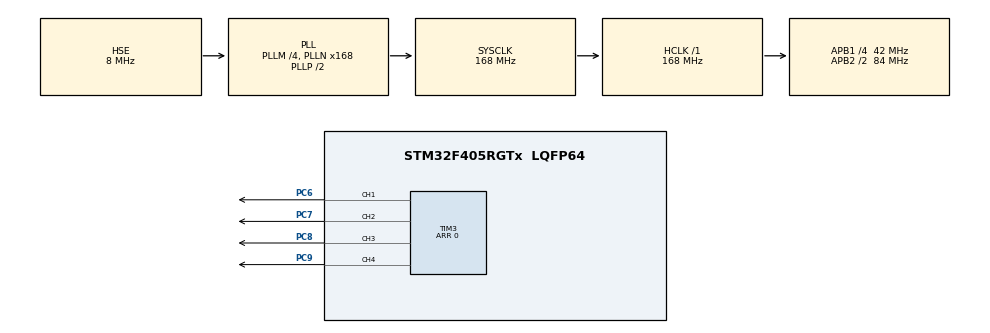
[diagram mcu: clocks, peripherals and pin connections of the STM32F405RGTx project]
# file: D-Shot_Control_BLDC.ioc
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Dma.Request0=TIM3_CH1/TRIG
Dma.Request1=TIM3_CH2
Dma.Request2=TIM3_CH3
Dma.Request3=TIM3_CH4/UP
Dma.TIM3_CH1/TRIG.0.Direction=DMA_MEMORY_TO_PERIPH
Dma.TIM3_CH1/TRIG.0.FIFOMode=DMA_FIFOMODE_ENABLE
Dma.TIM3_CH1/TRIG.0.FIFOThreshold=DMA_FIFO_THRESHOLD_1QUARTERFULL
Dma.TIM3_CH1/TRIG.0.Instance=DMA1_Stream4
Dma.TIM3_CH1/TRIG.0.MemBurst=DMA_MBURST_SINGLE
Dma.TIM3_CH1/TRIG.0.MemDataAlignment=DMA_MDATAALIGN_WORD
Dma.TIM3_CH1/TRIG.0.MemInc=DMA_MINC_ENABLE
Dma.TIM3_CH1/TRIG.0.Mode=DMA_NORMAL
Dma.TIM3_CH1/TRIG.0.PeriphBurst=DMA_PBURST_SINGLE
Dma.TIM3_CH1/TRIG.0.PeriphDataAlignment=DMA_PDATAALIGN_WORD
Dma.TIM3_CH1/TRIG.0.PeriphInc=DMA_PINC_DISABLE
Dma.TIM3_CH1/TRIG.0.Priority=DMA_PRIORITY_HIGH
Dma.TIM3_CH2.1.Direction=DMA_MEMORY_TO_PERIPH
Dma.TIM3_CH2.1.FIFOMode=DMA_FIFOMODE_ENABLE
Dma.TIM3_CH2.1.FIFOThreshold=DMA_FIFO_THRESHOLD_1QUARTERFULL
Dma.TIM3_CH2.1.Instance=DMA1_Stream5
Dma.TIM3_CH2.1.MemBurst=DMA_MBURST_SINGLE
Dma.TIM3_CH2.1.MemDataAlignment=DMA_MDATAALIGN_WORD
Dma.TIM3_CH2.1.MemInc=DMA_MINC_ENABLE
Dma.TIM3_CH2.1.Mode=DMA_NORMAL
Dma.TIM3_CH2.1.PeriphBurst=DMA_PBURST_SINGLE
Dma.TIM3_CH2.1.PeriphDataAlignment=DMA_PDATAALIGN_WORD
Dma.TIM3_CH2.1.PeriphInc=DMA_PINC_DISABLE
Dma.TIM3_CH2.1.Priority=DMA_PRIORITY_HIGH
Dma.TIM3_CH3.2.Direction=DMA_MEMORY_TO_PERIPH
Dma.TIM3_CH3.2.FIFOMode=DMA_FIFOMODE_ENABLE
Dma.TIM3_CH3.2.FIFOThreshold=DMA_FIFO_THRESHOLD_1QUARTERFULL
Dma.TIM3_CH3.2.Instance=DMA1_Stream7
Dma.TIM3_CH3.2.MemBurst=DMA_MBURST_SINGLE
Dma.TIM3_CH3.2.MemDataAlignment=DMA_MDATAALIGN_WORD
Dma.TIM3_CH3.2.MemInc=DMA_MINC_ENABLE
Dma.TIM3_CH3.2.Mode=DMA_NORMAL
Dma.TIM3_CH3.2.PeriphBurst=DMA_PBURST_SINGLE
Dma.TIM3_CH3.2.PeriphDataAlignment=DMA_PDATAALIGN_WORD
Dma.TIM3_CH3.2.PeriphInc=DMA_PINC_DISABLE
Dma.TIM3_CH3.2.Priority=DMA_PRIORITY_HIGH
Dma.TIM3_CH4/UP.3.Direction=DMA_MEMORY_TO_PERIPH
Dma.TIM3_CH4/UP.3.FIFOMode=DMA_FIFOMODE_ENABLE
Dma.TIM3_CH4/UP.3.FIFOThreshold=DMA_FIFO_THRESHOLD_1QUARTERFULL
Dma.TIM3_CH4/UP.3.Instance=DMA1_Stream2
Dma.TIM3_CH4/UP.3.MemBurst=DMA_MBURST_SINGLE
Dma.TIM3_CH4/UP.3.MemDataAlignment=DMA_MDATAALIGN_WORD
Dma.TIM3_CH4/UP.3.MemInc=DMA_MINC_ENABLE
Dma.TIM3_CH4/UP.3.Mode=DMA_NORMAL
Dma.TIM3_CH4/UP.3.PeriphBurst=DMA_PBURST_SINGLE
Dma.TIM3_CH4/UP.3.PeriphDataAlignment=DMA_PDATAALIGN_WORD
Dma.TIM3_CH4/UP.3.PeriphInc=DMA_PINC_DISABLE
Dma.TIM3_CH4/UP.3.Priority=DMA_PRIORITY_HIGH
Mcu.Family=STM32F4
Mcu.Name=STM32F405RGTx
Mcu.Package=LQFP64
NVIC.DMA1_Stream2_IRQn=true\:0\:0\:false\:false\:true\:false\:true\:true
NVIC.DMA1_Stream4_IRQn=true\:0\:0\:false\:false\:true\:false\:true\:true
NVIC.DMA1_Stream5_IRQn=true\:0\:0\:false\:false\:true\:false\:true\:true
NVIC.DMA1_Stream7_IRQn=true\:0\:0\:false\:false\:true\:false\:true\:true
NVIC.PriorityGroup=NVIC_PRIORITYGROUP_4
PA13.Mode=Serial_Wire
PA13.Signal=SYS_JTMS-SWDIO
PA14.Mode=Serial_Wire
PA14.Signal=SYS_JTCK-SWCLK
PC6.Signal=S_TIM3_CH1
PC7.Signal=S_TIM3_CH2
PC8.Signal=S_TIM3_CH3
PC9.Signal=S_TIM3_CH4
PH0-OSC_IN.Mode=HSE-External-Oscillator
PH0-OSC_IN.Signal=RCC_OSC_IN
PH1-OSC_OUT.Mode=HSE-External-Oscillator
PH1-OSC_OUT.Signal=RCC_OSC_OUT
ProjectManager.HeapSize=0x200
ProjectManager.StackSize=0x400
ProjectManager.TargetToolchain=STM32CubeIDE
RCC.48MHZClocksFreq_Value=84000000
RCC.AHBFreq_Value=168000000
RCC.APB1CLKDivider=RCC_HCLK_DIV4
RCC.APB1Freq_Value=42000000
RCC.APB1TimFreq_Value=84000000
RCC.APB2CLKDivider=RCC_HCLK_DIV2
RCC.APB2Freq_Value=84000000
RCC.APB2TimFreq_Value=168000000
RCC.CortexFreq_Value=168000000
RCC.HCLKFreq_Value=168000000
RCC.HSE_VALUE=8000000
RCC.HSI_VALUE=16000000
RCC.LSE_VALUE=32768
RCC.PLLM=4
RCC.PLLN=168
RCC.PLLSourceVirtual=RCC_PLLSOURCE_HSE
RCC.SYSCLKFreq_VALUE=168000000
RCC.SYSCLKSource=RCC_SYSCLKSOURCE_PLLCLK
RCC.VCOOutputFreq_Value=336000000
SH.S_TIM3_CH1.0=TIM3_CH1,PWM Generation1 CH1
SH.S_TIM3_CH2.0=TIM3_CH2,PWM Generation2 CH2
SH.S_TIM3_CH3.0=TIM3_CH3,PWM Generation3 CH3
SH.S_TIM3_CH4.0=TIM3_CH4,PWM Generation4 CH4
TIM3.Channel-PWM\ Generation1\ CH1=TIM_CHANNEL_1
TIM3.Channel-PWM\ Generation2\ CH2=TIM_CHANNEL_2
TIM3.Channel-PWM\ Generation3\ CH3=TIM_CHANNEL_3
TIM3.Channel-PWM\ Generation4\ CH4=TIM_CHANNEL_4
TIM3.Period=0
board=custom

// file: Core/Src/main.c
/* USER CODE BEGIN Header */
/**
  ******************************************************************************
  * @file           : main.c
  * @brief          : Main program body
  ******************************************************************************
  * @attention
  *
  * Copyright (c) 2023 STMicroelectronics.
  * All rights reserved.
  *
  * This software is licensed under terms that can be found in the LICENSE file
  * in the root directory of this software component.
  * If no LICENSE file comes with this software, it is provided AS-IS.
  *
  ******************************************************************************
  */
/* USER CODE END Header */
#include "main.h"
#include "dma.h"
#include "tim.h"
#include "gpio.h"

/* USER CODE BEGIN Includes */
#include "dshot.h"
/* USER CODE END Includes */

/* USER CODE BEGIN PV */
uint16_t Motor_Value[4] = {0, 0, 0, 0};
/* USER CODE END PV */

void SystemClock_Config(void);

int main(void)
{

  /* MCU Configuration--------------------------------------------------------*/

  /* Reset of all peripherals, Initializes the Flash interface and the Systick. */
  HAL_Init();

  /* Configure the system clock */
  SystemClock_Config();

  /* Initialize all configured peripherals */
  MX_GPIO_Init();
  MX_DMA_Init();
  MX_TIM3_Init();
  /* USER CODE BEGIN 2 */
  dshot_init(DSHOT600);
  /* USER CODE END 2 */

  /* Infinite loop */
  /* USER CODE BEGIN WHILE */
  while (1)
  {
	  dshot_write(Motor_Value);
	  HAL_Delay(1);
    /* USER CODE END WHILE */

  }
}

void SystemClock_Config(void)
{
  RCC_OscInitTypeDef RCC_OscInitStruct = {0};
  RCC_ClkInitTypeDef RCC_ClkInitStruct = {0};

  /** Configure the main internal regulator output voltage
  */
  __HAL_RCC_PWR_CLK_ENABLE();
  __HAL_PWR_VOLTAGESCALING_CONFIG(PWR_REGULATOR_VOLTAGE_SCALE1);

  /** Initializes the RCC Oscillators according to the specified parameters
  * in the RCC_OscInitTypeDef structure.
  */
  RCC_OscInitStruct.OscillatorType = RCC_OSCILLATORTYPE_HSE;
  RCC_OscInitStruct.HSEState = RCC_HSE_ON;
  RCC_OscInitStruct.PLL.PLLState = RCC_PLL_ON;
  RCC_OscInitStruct.PLL.PLLSource = RCC_PLLSOURCE_HSE;
  RCC_OscInitStruct.PLL.PLLM = 4;
  RCC_OscInitStruct.PLL.PLLN = 168;
  RCC_OscInitStruct.PLL.PLLP = RCC_PLLP_DIV2;
  RCC_OscInitStruct.PLL.PLLQ = 4;
  if (HAL_RCC_OscConfig(&RCC_OscInitStruct) != HAL_OK)
  {
    Error_Handler();
  }

  /** Initializes the CPU, AHB and APB buses clocks
  */
  RCC_ClkInitStruct.ClockType = RCC_CLOCKTYPE_HCLK|RCC_CLOCKTYPE_SYSCLK
                              |RCC_CLOCKTYPE_PCLK1|RCC_CLOCKTYPE_PCLK2;
  RCC_ClkInitStruct.SYSCLKSource = RCC_SYSCLKSOURCE_PLLCLK;
  RCC_ClkInitStruct.AHBCLKDivider = RCC_SYSCLK_DIV1;
  RCC_ClkInitStruct.APB1CLKDivider = RCC_HCLK_DIV4;
  RCC_ClkInitStruct.APB2CLKDivider = RCC_HCLK_DIV2;

  if (HAL_RCC_ClockConfig(&RCC_ClkInitStruct, FLASH_LATENCY_5) != HAL_OK)
  {
    Error_Handler();
  }
}

void Error_Handler(void)
{
  __disable_irq();
  while (1)
  {
  }
}
